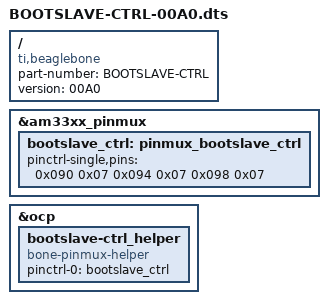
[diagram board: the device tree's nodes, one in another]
/dts-v1/;
/plugin/;

// Configuration Bits
// Bit                     1 :                   0
// 5    Receive Enable       :     Receive Disable
// 4    Pullup               :            Pulldown
// 3    Pullup/down Disabled : Pullup/down Enabled
// 2, 1, 0     Mode

/ {
    compatible = "ti,beaglebone", "ti,beaglebone-black";

    part-number = "BOOTSLAVE-CTRL";
    version = "00A0";

    fragment@0 {
        target = <&am33xx_pinmux>;
        __overlay__ {
            bootslave_ctrl: pinmux_bootslave_ctrl {
                pinctrl-single,pins = <
                    // Default pinmux and modes for these pins.
                    // addr with 0x44e10 as the start, mode bits
                    // NOTE: for the fisrt value: 0x0.. means prefix 0x44e18
					// NOTE: for the first value: 0x1.. means prefix 0x44e19
                    0x090 0x07 // P8_07: GPIO2_2 INP PD PD-ENABLE Mode7, GPIO
                    0x094 0x07 // P8_08: GPIO2_3 INP PD PD-ENABLE Mode7, GPIO
                    0x098 0x07 // P8_10: GPIO2_4 INP PD PD-ENABLE Mode7, GPIO
                >;
            };
        };
    };

    fragment@1 {
        target = <&ocp>;
        __overlay__ {
            bootslave-ctrl_helper {
                compatible = "bone-pinmux-helper";
                pinctrl-names = "default";
                pinctrl-0 = <&bootslave_ctrl>;
                status = "okay";
            };
        };
    };
};

// convert to .dtbo file:
// dtc -O dtb -o BOOTSLAVE-CTRL-00A0.dtbo -b O -@ BOOTSLAVE-CTRL-00A0.dts
// Copy the compiled file (*.dtbo) to the /lib/firmware directory.

// To enable it manually, check the current overlays:
// # cat /sys/devices/bone_capemgr.9/slots
//  0: 54:PF--- 
//  1: 55:PF--- 
//  2: 56:PF--- 
//  3: 57:PF--- 
//  4: ff:P-O-L Bone-LT-eMMC-2G,00A0,Texas Instrument,BB-BONE-EMMC-2G
//  5: ff:P-O-L Bone-Black-HDMI,00A0,Texas Instrument,BB-BONELT-HDMI

// Manually enable the overlay:
// echo BOOTSLAVE-CTRL > /sys/devices/bone_capemgr.*/slots

// Check it again to ensure it worked and did't disable other stuff:
// # cat /sys/devices/bone_capemgr.9/slots
//  0: 54:PF--- 
//  1: 55:PF--- 
//  2: 56:PF--- 
//  3: 57:PF--- 
//  4: ff:P-O-L Bone-LT-eMMC-2G,00A0,Texas Instrument,BB-BONE-EMMC-2G
//  5: ff:P-O-L Bone-Black-HDMI,00A0,Texas Instrument,BB-BONELT-HDMI
//  7: ff:P-O-L Override Board Name,00A0,Override Manuf,BOOTSLAVE-CTRL
//
// Excellent.

// Now, to have it enabled on boot:
// In this file: /boot/uboot/uEnv.txt
// add these lines before the variable optargs is used:
//
// ## Enable BOOTSLAVE-CTRL so I can control a slaved BBB for OS development.
// ## psilord <date>
// optargs=capemgr.enable_partno=BOOTSLAVE-CTRL
//
// HOWEVER:
// Due to limitations in debian wheezy's userspace, the use of an initramfs,
// and having firmware builtin to the kernel. It is currently not possible to
// load "custom" capes via: capemgr.enable_partno=xyz. Instead an init script
// has been setup to load the cape/capes as soon as possible.
// 
// So, in addition we add the cape to the CAPE variable in 
// /etc/default/capemgr
//
// CAPE="BOOTSLAVE-CTRL"

// Verification that it worked:

// Then after booting or installing the device overlay, we query the pins
// we care about to see their status:
// # cat /sys/kernel/debug/pinctrl/44e10800.pinmux/pins | egrep -e '(890|894|898)'
// pin 36 (44e10890) 00000007 pinctrl-single 
// pin 37 (44e10894) 00000007 pinctrl-single 
// pin 38 (44e10898) 00000007 pinctrl-single 

// The above modes are correct.

// # cat /sys/kernel/debug/pinctrl/44e10800.pinmux/pinmux-pins | egrep -e '(890|894|898)'
// 
// pin 36 (44e10890): bootslave-ctrl_helper.15 (GPIO UNCLAIMED) function pinmux_bootslave_ctrl group pinmux_bootslave_ctrl
// pin 37 (44e10894): bootslave-ctrl_helper.15 (GPIO UNCLAIMED) function pinmux_bootslave_ctrl group pinmux_bootslave_ctrl
// pin 38 (44e10898): bootslave-ctrl_helper.15 (GPIO UNCLAIMED) function pinmux_bootslave_ctrl group pinmux_bootslave_ctrl

// The above functions are devoted to BOOTSLAVE-CTRL

// Excellent
